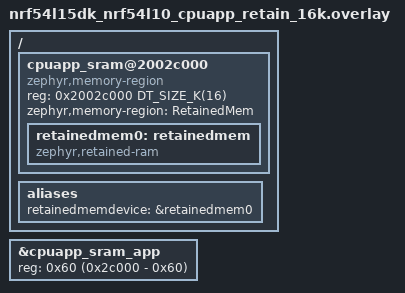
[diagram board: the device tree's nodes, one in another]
/ {
	cpuapp_sram@2002c000 {
		compatible = "zephyr,memory-region", "mmio-sram";
		reg = <0x2002c000 DT_SIZE_K(16)>;
		zephyr,memory-region = "RetainedMem";
		status = "okay";

		retainedmem0: retainedmem {
			compatible = "zephyr,retained-ram";
			status = "okay";
		};
	};

	aliases {
		retainedmemdevice = &retainedmem0;
	};
};

&cpuapp_sram_app {
	/* Shrink SRAM size to avoid overlap with retained memory region:
	 * 192 - 16 = 176KB = 0x2c000
	 */
	reg = <0x60 (0x2c000 - 0x60)>;
};
